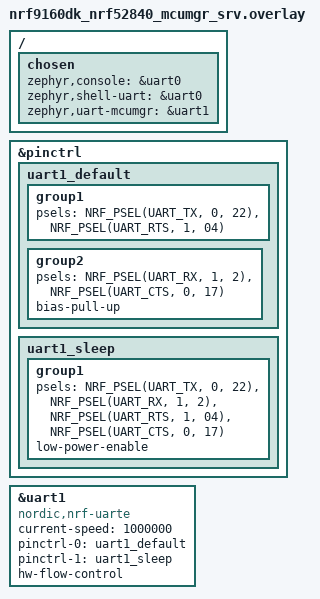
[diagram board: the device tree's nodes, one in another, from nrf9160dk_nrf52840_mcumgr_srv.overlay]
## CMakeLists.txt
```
#
# Copyright (c) 2023 Nordic Semiconductor
#
# SPDX-License-Identifier: LicenseRef-Nordic-5-Clause
#

cmake_minimum_required(VERSION 3.20.0)

find_package(Zephyr REQUIRED HINTS $ENV{ZEPHYR_BASE})
project(smp_client)
zephyr_compile_definitions(PROJECT_NAME=${PROJECT_NAME})

# NORDIC SDK APP START
target_sources(app PRIVATE src/main.c)
zephyr_include_directories(src)
# NORDIC SDK APP END
```

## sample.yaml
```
sample:
  name: smp_svr Sample
tests:
  sample.cellular.smp_svr:
    sysbuild: true
    build_only: true
    integration_platforms:
      - nrf9160dk/nrf52840
    platform_allow: nrf9160dk/nrf52840
    extra_args: EXTRA_DTC_OVERLAY_FILE="nrf9160dk_nrf52840_mcumgr_srv.overlay"
    tags:
      - ci_build
      - sysbuild
      - ci_samples_cellular
```

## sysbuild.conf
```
#
# Copyright (c) 2024 Nordic Semiconductor
#
# SPDX-License-Identifier: LicenseRef-Nordic-5-Clause
#

SB_CONFIG_BOOTLOADER_MCUBOOT=y
SB_CONFIG_PM_EXTERNAL_FLASH_MCUBOOT_SECONDARY=n
```

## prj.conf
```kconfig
# Enale Flash
CONFIG_FLASH=y
CONFIG_FLASH_MAP=y
CONFIG_STREAM_FLASH=y

# Ensure an MCUboot-compatible binary is generated.
CONFIG_BOOTLOADER_MCUBOOT=y
CONFIG_MCUBOOT_BOOTUTIL_LIB=y

CONFIG_IMG_MANAGER=y
CONFIG_MCUBOOT_IMG_MANAGER=y
# App image version
CONFIG_MCUBOOT_IMGTOOL_SIGN_VERSION="1.0.0"

# Enable logging
CONFIG_LOG=y
CONFIG_MCUBOOT_UTIL_LOG_LEVEL_WRN=y

# Enable shell
CONFIG_CONSOLE=y
CONFIG_SHELL=y
CONFIG_MCUBOOT_SHELL=y
# Disable debug logging
CONFIG_LOG_MAX_LEVEL=3
```

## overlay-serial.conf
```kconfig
# Some command handlers require a large stack.
CONFIG_SYSTEM_WORKQUEUE_STACK_SIZE=2304
CONFIG_MAIN_STACK_SIZE=2048

# Enable MCUmgr and dependencies.
CONFIG_NET_BUF=y
CONFIG_ZCBOR=y
CONFIG_CRC=y
CONFIG_MCUMGR=y

# Enable the serial MCUmgr transport.
CONFIG_BASE64=y
CONFIG_MCUMGR_TRANSPORT_UART=y

# Enable most core commands.
CONFIG_MCUMGR_GRP_IMG=y
CONFIG_MCUMGR_GRP_OS=y
```

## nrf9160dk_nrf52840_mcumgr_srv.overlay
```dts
/*
 * Copyright (c) 2023 Nordic Semiconductor ASA
 *
 * SPDX-License-Identifier: LicenseRef-Nordic-5-Clause
 */

#include <nrf52840/nrf9160dk_uart1_on_if0_3.dtsi>

&pinctrl {
	uart1_default: uart1_default {
		group1 {
			psels = <NRF_PSEL(UART_TX, 0, 22)>,
				<NRF_PSEL(UART_RTS, 1, 04)>;
		};
		group2 {
			psels = <NRF_PSEL(UART_RX, 1, 2)>,
				<NRF_PSEL(UART_CTS, 0, 17)>;
			bias-pull-up;
		};
	};

	uart1_sleep: uart1_sleep {
		group1 {
			psels =<NRF_PSEL(UART_TX, 0, 22)>,
				<NRF_PSEL(UART_RX, 1, 2)>,
				<NRF_PSEL(UART_RTS, 1, 04)>,
				<NRF_PSEL(UART_CTS, 0, 17)>;
			low-power-enable;
		};
	};

};

&uart1 {
	compatible = "nordic,nrf-uarte";
	current-speed = <1000000>;
	pinctrl-0 = <&uart1_default>;
	pinctrl-1 = <&uart1_sleep>;
	hw-flow-control;
};

/ {
        chosen {
                zephyr,console = &uart0;
                zephyr,shell-uart = &uart0;
                zephyr,uart-mcumgr = &uart1;
        };
};
```

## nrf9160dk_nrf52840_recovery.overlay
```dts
/*
 * Copyright (c) 2023 Nordic Semiconductor ASA
 *
 * SPDX-License-Identifier: LicenseRef-Nordic-5-Clause
 */

#include <nrf52840/nrf9160dk_nrf52840_reset_on_if9.dtsi>
```

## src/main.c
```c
/*
 * Copyright (c) 2023 Nordic Semiconductor ASA
 *
 * SPDX-License-Identifier: LicenseRef-Nordic-5-Clause
 */

#include <pm_config.h>
#include <zephyr/kernel.h>
#include <zephyr/stats/stats.h>
#include <zephyr/usb/usb_device.h>
#include <zephyr/dfu/mcuboot.h>

#include <zephyr/logging/log.h>
LOG_MODULE_REGISTER(app_smp_svr, CONFIG_LOG_DEFAULT_LEVEL);

static void image_validation(void)
{
	int rc;
	char buf[255];
	struct mcuboot_img_header header;

	boot_read_bank_header(PM_MCUBOOT_PRIMARY_ID, &header, sizeof(header));
	snprintk(buf, sizeof(buf), "%d.%d.%d-%d", header.h.v1.sem_ver.major,
		 header.h.v1.sem_ver.minor, header.h.v1.sem_ver.revision,
		 header.h.v1.sem_ver.build_num);

	LOG_INF("Booting image: build time: " __DATE__ " " __TIME__);
	LOG_INF("Image Version %s", buf);
	rc = boot_is_img_confirmed();
	LOG_INF("Image is%s confirmed OK", rc ? "" : " not");
	if (!rc) {
		if (boot_write_img_confirmed()) {
			LOG_ERR("Failed to confirm image");
		} else {
			LOG_INF("Marked image as OK");
		}
	}
}

int main(void)
{
	image_validation();

	while (1) {
		k_sleep(K_MSEC(10000));
	}
	return 0;
}
```
